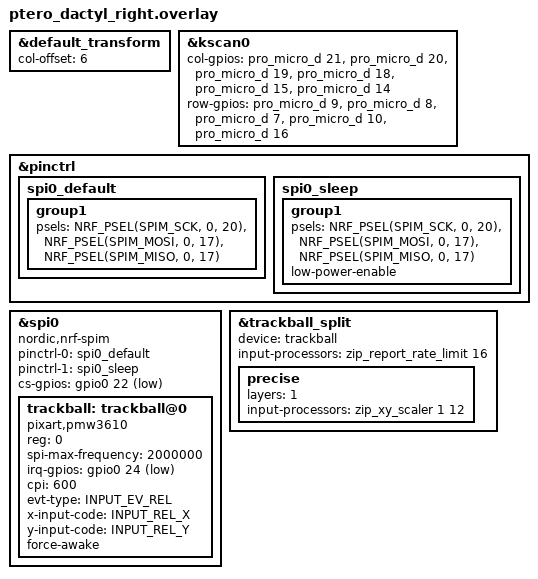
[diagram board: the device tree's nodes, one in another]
// This file was generated from a template. Edit it to match your keyboard.
// See https://zmk.dev/docs/development/hardware-integration/new-shield for more
// instructions.

#include "ptero_dactyl.dtsi"
#include <dt-bindings/zmk/input_transform.h>
#include <zephyr/dt-bindings/input/input-event-codes.h>
#include <input/processors.dtsi>

&default_transform {
    col-offset = <6>;
};

&kscan0 {
    // Replace these comments with the GPIO pins in the matrix for the right side.
    // See https://zmk.dev/docs/development/hardware-integration/new-shield#shield-overlays
    col-gpios
        = <&pro_micro_d 21 GPIO_ACTIVE_HIGH>
        , <&pro_micro_d 20 GPIO_ACTIVE_HIGH>
        , <&pro_micro_d 19 GPIO_ACTIVE_HIGH>
        , <&pro_micro_d 18 GPIO_ACTIVE_HIGH>
        , <&pro_micro_d 15 GPIO_ACTIVE_HIGH>
        , <&pro_micro_d 14 GPIO_ACTIVE_HIGH>
        ;

    row-gpios
        = <&pro_micro_d 9  (GPIO_ACTIVE_HIGH | GPIO_PULL_DOWN)>
        , <&pro_micro_d 8  (GPIO_ACTIVE_HIGH | GPIO_PULL_DOWN)>
        , <&pro_micro_d 7  (GPIO_ACTIVE_HIGH | GPIO_PULL_DOWN)>
        , <&pro_micro_d 10 (GPIO_ACTIVE_HIGH | GPIO_PULL_DOWN)>
        , <&pro_micro_d 16 (GPIO_ACTIVE_HIGH | GPIO_PULL_DOWN)>
        ;
};

&pinctrl {
    spi0_default: spi0_default {
        group1 {
            psels = <NRF_PSEL(SPIM_SCK, 0, 20)>,
                <NRF_PSEL(SPIM_MOSI, 0, 17)>,
                <NRF_PSEL(SPIM_MISO, 0, 17)>;
        };
    };

    spi0_sleep: spi0_sleep {
        group1 {
            psels = <NRF_PSEL(SPIM_SCK, 0, 20)>,
                <NRF_PSEL(SPIM_MOSI, 0, 17)>,
                <NRF_PSEL(SPIM_MISO, 0, 17)>;
            low-power-enable;
        };
    };
};

&spi0 {
    status = "okay";
    compatible = "nordic,nrf-spim";
    pinctrl-0 = <&spi0_default>;
    pinctrl-1 = <&spi0_sleep>;
    pinctrl-names = "default", "sleep";
    cs-gpios = <&gpio0 22 GPIO_ACTIVE_LOW>;

    trackball: trackball@0 {
        status = "okay";
        compatible = "pixart,pmw3610";
        reg = <0>;
        spi-max-frequency = <2000000>;
        irq-gpios = <&gpio0 24 (GPIO_ACTIVE_LOW | GPIO_PULL_UP)>;
        cpi = <600>;
        evt-type = <INPUT_EV_REL>;
        x-input-code = <INPUT_REL_X>;
        y-input-code = <INPUT_REL_Y>;

        force-awake;
        /* keep the sensor awake while ZMK activity state is ACTIVE,
           fallback to normal downshift mode after ZMK goes into IDLE / SLEEP mode.
           thus, the sensor would be a `wakeup-source` */
    };
};

#include <input/processors/report_rate_limit.dtsi>

&trackball_split {
    device = <&trackball>;

    input-processors = <&zip_report_rate_limit 16>;

    precise {
        layers = <1>;
        input-processors = <&zip_xy_scaler 1 12>;
    };
};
